AUTOSAR XML (schema 4-2-2)
# Copyright 2016 Mentor Graphics Corporation
# All Rights Reserved
# THIS WORK CONTAINS TRADE SECRET
# AND PROPRIETARY INFORMATION WHICH IS THE
# PROPERTY OF MENTOR GRAPHICS
# CORPORATION OR ITS LICENSORS AND IS
# SUBJECT TO LICENSE TERMS.
package /AUTOSAR/Services/ComM
  swc implementation IMPL_ComM: programming-language=C, sw-version=5.1.1, swc-bsw-mapping=SwcBswMapping_ComM, used-code-generator=VSC, vendor-id=31, behavior=SWCIB_ComM
    resource consumption RC_ComM
      memory section CODE: alignment=UNSPECIFIED, sw-addrmethod=CODE
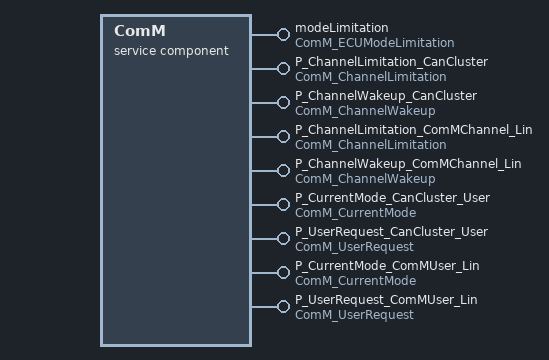
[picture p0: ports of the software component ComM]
  service sw component type ComM
    9 x provide port:
      modeLimitation: provided-interface=ComM_ECUModeLimitation  # ComM_ECUModeLimitation client-server interface for the ECU
      P_ChannelLimitation_CanCluster: provided-interface=ComM_ChannelLimitation  # ComM_ChannelLimitation client-server interface for channel 0: CanCluster
      P_ChannelWakeup_CanCluster: provided-interface=ComM_ChannelWakeup  # ComM_ChannelWakeup client-server interface for channel 0: CanCluster
      P_ChannelLimitation_ComMChannel_Lin: provided-interface=ComM_ChannelLimitation  # ComM_ChannelLimitation client-server interface for channel 1: ComMChannel_Lin
      P_ChannelWakeup_ComMChannel_Lin: provided-interface=ComM_ChannelWakeup  # ComM_ChannelWakeup client-server interface for channel 1: ComMChannel_Lin
      P_CurrentMode_CanCluster_User: provided-interface=ComM_CurrentMode  # ComM_CurrentMode client-server interface for user 0: CanCluster_User
      P_UserRequest_CanCluster_User: provided-interface=ComM_UserRequest  # ComM_UserRequest client-server interface for user 0: CanCluster_User
      P_CurrentMode_ComMUser_Lin: provided-interface=ComM_CurrentMode  # ComM_CurrentMode client-server interface for user 1: ComMUser_Lin
      P_UserRequest_ComMUser_Lin: provided-interface=ComM_UserRequest  # ComM_UserRequest client-server interface for user 1: ComMUser_Lin
    behavior SWCIB_ComM: data-type-mapping=ComMModeMappingSet
      14 x operation invoked event:
        OI_CL000_GetInhibitionStatus: start-on-event=GetInhibitionStatus, operation=P_ChannelLimitation_CanCluster.GetInhibitionStatus
        OI_CL000_LimitChannelToNoComMode: start-on-event=LimitChannelToNoComMode, operation=P_ChannelLimitation_CanCluster.LimitChannelToNoComMode
        OI_CW000_PreventWakeUp: start-on-event=PreventWakeUp, operation=P_ChannelWakeup_CanCluster.PreventWakeUp
        OI_CL001_GetInhibitionStatus: start-on-event=GetInhibitionStatus, operation=P_ChannelLimitation_ComMChannel_Lin.GetInhibitionStatus
        OI_CL001_LimitChannelToNoComMode: start-on-event=LimitChannelToNoComMode, operation=P_ChannelLimitation_ComMChannel_Lin.LimitChannelToNoComMode
        OI_CW001_PreventWakeUp: start-on-event=PreventWakeUp, operation=P_ChannelWakeup_ComMChannel_Lin.PreventWakeUp
        OI_UR000_GetCurrentComMode: start-on-event=GetCurrentComMode, operation=P_UserRequest_CanCluster_User.GetCurrentComMode
        OI_UR000_GetMaxComMode: start-on-event=GetMaxComMode, operation=P_UserRequest_CanCluster_User.GetMaxComMode
        OI_UR000_GetRequestedComMode: start-on-event=GetRequestedComMode, operation=P_UserRequest_CanCluster_User.GetRequestedComMode
        OI_UR000_RequestComMode: start-on-event=RequestComMode, operation=P_UserRequest_CanCluster_User.RequestComMode
        OI_UR001_GetCurrentComMode: start-on-event=GetCurrentComMode, operation=P_UserRequest_ComMUser_Lin.GetCurrentComMode
        OI_UR001_GetMaxComMode: start-on-event=GetMaxComMode, operation=P_UserRequest_ComMUser_Lin.GetMaxComMode
        OI_UR001_GetRequestedComMode: start-on-event=GetRequestedComMode, operation=P_UserRequest_ComMUser_Lin.GetRequestedComMode
        OI_UR001_RequestComMode: start-on-event=RequestComMode, operation=P_UserRequest_ComMUser_Lin.RequestComMode
      port-api-options:
        modeLimitation
        {port-defined-argument-value{value=0, value-type=NetworkHandleType}, port=P_ChannelLimitation_CanCluster}
        {port-defined-argument-value{value=0, value-type=NetworkHandleType}, port=P_ChannelWakeup_CanCluster}
        {port-defined-argument-value{value=1, value-type=NetworkHandleType}, port=P_ChannelLimitation_ComMChannel_Lin}
        {port-defined-argument-value{value=1, value-type=NetworkHandleType}, port=P_ChannelWakeup_ComMChannel_Lin}
        {port-defined-argument-value{value=0, value-type=ComM_UserHandleType}, port=P_UserRequest_CanCluster_User}
        {port-defined-argument-value{value=0, value-type=uint8}, port=P_CurrentMode_CanCluster_User}
        {port-defined-argument-value{value=1, value-type=ComM_UserHandleType}, port=P_UserRequest_ComMUser_Lin}
        {port-defined-argument-value{value=1, value-type=uint8}, port=P_CurrentMode_ComMUser_Lin}
      11 x runnable:
        LimitECUToNoComMode: symbol=ComM_LimitECUToNoComMode
        SetECUGroupClassification: symbol=ComM_SetECUGroupClassification
        LimitChannelToNoComMode: symbol=ComM_LimitChannelToNoComMode
        GetInhibitionStatus: symbol=ComM_GetInhibitionStatus
        PreventWakeUp: symbol=ComM_PreventWakeUp
        RequestComMode: can-be-invoked-concurrently=true, symbol=ComM_RequestComMode
        GetMaxComMode: can-be-invoked-concurrently=true, symbol=ComM_GetMaxComMode
        GetRequestedComMode: can-be-invoked-concurrently=true, symbol=ComM_GetRequestedComMode
        GetCurrentComMode: can-be-invoked-concurrently=true, symbol=ComM_GetCurrentComMode
        ComM_MainFunction_0
          mode switch point ComMMode_000: mode-group=P_CurrentMode_CanCluster_User.currentMode
          mode switch point ComMMode_001: mode-group=P_CurrentMode_ComMUser_Lin.currentMode
        ComM_MainFunction_1
          mode switch point ComMMode_000: mode-group=P_CurrentMode_CanCluster_User.currentMode
          mode switch point ComMMode_001: mode-group=P_CurrentMode_ComMUser_Lin.currentMode
  4 x client server interface, all with is-service=true:
    ComM_ChannelLimitation
      operation GetInhibitionStatus: possible-error=ComM_ChannelLimitation/E_NOT_OK
        arg Status: type=ComM_InhibitionStatusType, direction=OUT
      operation LimitChannelToNoComMode: possible-error=ComM_ChannelLimitation/E_NOT_OK
        arg Status: type=boolean, direction=IN
      error E_NOT_OK: error-code=1
    ComM_ChannelWakeup
      operation PreventWakeUp: possible-error=ComM_ChannelWakeup/E_NOT_OK
        arg Status: type=boolean, direction=IN
      error E_NOT_OK: error-code=1
    ComM_ECUModeLimitation
      operation LimitECUToNoComMode: possible-error=ComM_ECUModeLimitation/E_NOT_OK
        arg Status: type=boolean, direction=IN
      operation SetECUGroupClassification: possible-error=ComM_ECUModeLimitation/E_NOT_OK
        arg Status: type=ComM_InhibitionStatusType, direction=IN
      error E_NOT_OK: error-code=1
    ComM_UserRequest
      4 x operation:
        RequestComMode: possible-error=[E_MODE_LIMITATION, ComM_UserRequest/E_NOT_OK]
          arg ComMode: type=ComM_ModeType, direction=IN
        GetRequestedComMode: possible-error=ComM_UserRequest/E_NOT_OK
          arg ComMode: type=ComM_ModeType, direction=OUT
        GetMaxComMode: possible-error=ComM_UserRequest/E_NOT_OK
          arg ComMode: type=ComM_ModeType, direction=OUT
        GetCurrentComMode: possible-error=ComM_UserRequest/E_NOT_OK
          arg ComMode: type=ComM_ModeType, direction=OUT
      error E_MODE_LIMITATION: error-code=2
      error E_NOT_OK: error-code=1
  mode switch interface ComM_CurrentMode: is-service=true
    mode group currentMode: type=ComMMode
  sender receiver interface ComM_CurrentChannelRequest: is-service=true
    data fullComRequestors: type=ComM_UserHandleArrayType
  impl type ComM_InhibitionStatusType: compu {mask 1: 1=WakeUpInhibitionActive, mask 2: 2=LimitedToNoCom}, range phys 1..255, implementation-data-type=uint8
  impl type ComM_ModeType: compu {0=COMM_NO_COMMUNICATION, 1=COMM_SILENT_COMMUNICATION, 2=COMM_FULL_COMMUNICATION}, range phys 0..255, implementation-data-type=uint8
  impl type ComM_UserHandleType: implementation-data-type=uint8
  impl type NetworkHandleType: category=VALUE, base-type=uint8, type-emitter=BSW
  impl type ComM_UserHandleArrayType: category=STRUCTURE
    element numberOfRequesters: implementation-data-type=uint8
    element handleArray: category=ARRAY
      element handleArraySub: array-size=2, array-size-semantics=FIXED-SIZE, implementation-data-type=ComM_UserHandleType
  mode declaration group ComMMode: category=EXPLICIT_ORDER, initial-mode=NO_COMMUNICATION, on-transition-value=255
    mode NO_COMMUNICATION: value=0
    mode SILENT_COMMUNICATION: value=1
    mode FULL_COMMUNICATION: value=2
  data type mapping set ComMModeMappingSet: mode-request-type-map{implementation-data-type=uint8, mode-group=ComMMode}
  swc bsw mapping SwcBswMapping_ComM: bsw-behavior=BswBehavior_ComM, swc-behavior=SWCIB_ComM
    runnable-mappings:
      bsw-entity=ComM_MainFunction_0, swc-runnable=ComM_MainFunction_0
      bsw-entity=ComM_MainFunction_1, swc-runnable=ComM_MainFunction_1
